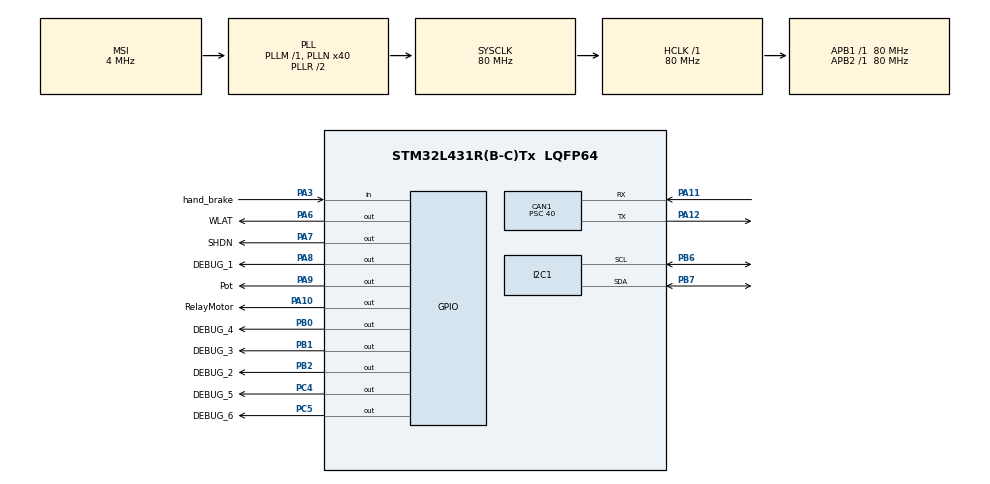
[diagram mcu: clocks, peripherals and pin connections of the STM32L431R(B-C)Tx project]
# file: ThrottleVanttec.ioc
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CAN1.BS1=CAN_BS1_13TQ
CAN1.BS2=CAN_BS2_2TQ
CAN1.CalculateBaudRate=125000
CAN1.CalculateTimeBit=8000
CAN1.CalculateTimeQuantum=500.0
CAN1.Prescaler=40
FREERTOS.Tasks01=defaultTask,24,128,StartDefaultTask,Default,NULL,Dynamic,NULL,NULL
FREERTOS.configTOTAL_HEAP_SIZE=16000
FREERTOS.configUSE_NEWLIB_REENTRANT=1
I2C1.Timing=0x10909CEC
Mcu.Family=STM32L4
Mcu.Name=STM32L431R(B-C)Tx
Mcu.Package=LQFP64
NVIC.PriorityGroup=NVIC_PRIORITYGROUP_4
PA10.GPIO_Label=RelayMotor
PA10.Signal=GPIO_Output
PA11.Mode=CAN_Activate
PA11.Signal=CAN1_RX
PA12.Mode=CAN_Activate
PA12.Signal=CAN1_TX
PA3.GPIO_Label=hand_brake
PA3.Signal=GPIO_Input
PA6.GPIO_Label=WLAT
PA6.Signal=GPIO_Output
PA7.GPIO_Label=SHDN
PA7.Signal=GPIO_Output
PA8.GPIO_Label=DEBUG_1
PA8.Signal=GPIO_Output
PA9.GPIO_Label=Pot
PA9.Signal=GPIO_Output
PB0.GPIO_Label=DEBUG_4
PB0.Signal=GPIO_Output
PB1.GPIO_Label=DEBUG_3
PB1.Signal=GPIO_Output
PB2.GPIO_Label=DEBUG_2
PB2.Signal=GPIO_Output
PB6.Mode=I2C
PB6.Signal=I2C1_SCL
PB7.Mode=I2C
PB7.Signal=I2C1_SDA
PC4.GPIO_Label=DEBUG_5
PC4.Signal=GPIO_Output
PC5.GPIO_Label=DEBUG_6
PC5.Signal=GPIO_Output
ProjectManager.HeapSize=0x200
ProjectManager.StackSize=0x400
ProjectManager.TargetToolchain=STM32CubeIDE
RCC.AHBFreq_Value=80000000
RCC.APB1Freq_Value=80000000
RCC.APB1TimFreq_Value=80000000
RCC.APB2Freq_Value=80000000
RCC.APB2TimFreq_Value=80000000
RCC.CortexFreq_Value=80000000
RCC.HCLKFreq_Value=80000000
RCC.HSE_VALUE=8000000
RCC.HSI48_VALUE=48000000
RCC.HSI_VALUE=16000000
RCC.LSE_VALUE=32768
RCC.MSI_VALUE=4000000
RCC.PLLN=40
RCC.SYSCLKFreq_VALUE=80000000
RCC.SYSCLKSource=RCC_SYSCLKSOURCE_PLLCLK
RCC.VCOOutputFreq_Value=160000000
VP_FREERTOS_VS_CMSIS_V2.Mode=CMSIS_V2
board=custom

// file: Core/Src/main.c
/* USER CODE BEGIN Header */
/**
  ******************************************************************************
  * @file           : main.c
  * @brief          : Main program body
  ******************************************************************************
  * @attention
  *
  * Copyright (c) 2023 STMicroelectronics.
  * All rights reserved.
  *
  * This software is licensed under terms that can be found in the LICENSE file
  * in the root directory of this software component.
  * If no LICENSE file comes with this software, it is provided AS-IS.
  *
  ******************************************************************************
  */
/* USER CODE END Header */
#include "main.h"
#include "cmsis_os.h"

/* USER CODE BEGIN Includes */
#include "mcp45hvx1.h"
#include "throttle_tasks.h"
#include "requirements.h"
#include "vanttec_sdv_ids.h"

/* USER CODE END Includes */

CAN_HandleTypeDef hcan1;

I2C_HandleTypeDef hi2c1;

/* Definitions for defaultTask */
osThreadId_t defaultTaskHandle;
const osThreadAttr_t defaultTask_attributes = {
  .name = "defaultTask",
  .stack_size = 128 * 4,
  .priority = (osPriority_t) osPriorityNormal,
};

void SystemClock_Config(void);
static void MX_GPIO_Init(void);
static void MX_CAN1_Init(void);
static void MX_I2C1_Init(void);
void StartDefaultTask(void *argument);

int main(void)
{

  /* MCU Configuration--------------------------------------------------------*/

  /* Reset of all peripherals, Initializes the Flash interface and the Systick. */
  HAL_Init();

  /* Configure the system clock */
  SystemClock_Config();

  /* Initialize all configured peripherals */
  MX_GPIO_Init();
  MX_CAN1_Init();
  MX_I2C1_Init();
  /* USER CODE BEGIN 2 */
  init_canlib(hcan1, VANTTEC_CAN_ID_THROTTLE_TX);
  init_canlib_tx();
  init_canlib_rx();
  canlib_init_generic_tasks();
  //init_ping_task();
  initialize_devices();
  begin_pot();
  init_requirements_task();
  init_throttle_tasks();
  /* USER CODE END 2 */

  /* Init scheduler */
  osKernelInitialize();

  /* Create the thread(s) */
  /* creation of defaultTask */
  defaultTaskHandle = osThreadNew(StartDefaultTask, NULL, &defaultTask_attributes);

  /* Start scheduler */
  osKernelStart();

  /* We should never get here as control is now taken by the scheduler */
  /* Infinite loop */
  while (1)
  {

  }
}

void SystemClock_Config(void)
{
  RCC_OscInitTypeDef RCC_OscInitStruct = {0};
  RCC_ClkInitTypeDef RCC_ClkInitStruct = {0};

  /** Configure the main internal regulator output voltage
  */
  if (HAL_PWREx_ControlVoltageScaling(PWR_REGULATOR_VOLTAGE_SCALE1) != HAL_OK)
  {
    Error_Handler();
  }

  /** Initializes the RCC Oscillators according to the specified parameters
  * in the RCC_OscInitTypeDef structure.
  */
  RCC_OscInitStruct.OscillatorType = RCC_OSCILLATORTYPE_MSI;
  RCC_OscInitStruct.MSIState = RCC_MSI_ON;
  RCC_OscInitStruct.MSICalibrationValue = 0;
  RCC_OscInitStruct.MSIClockRange = RCC_MSIRANGE_6;
  RCC_OscInitStruct.PLL.PLLState = RCC_PLL_ON;
  RCC_OscInitStruct.PLL.PLLSource = RCC_PLLSOURCE_MSI;
  RCC_OscInitStruct.PLL.PLLM = 1;
  RCC_OscInitStruct.PLL.PLLN = 40;
  RCC_OscInitStruct.PLL.PLLP = RCC_PLLP_DIV7;
  RCC_OscInitStruct.PLL.PLLQ = RCC_PLLQ_DIV2;
  RCC_OscInitStruct.PLL.PLLR = RCC_PLLR_DIV2;
  if (HAL_RCC_OscConfig(&RCC_OscInitStruct) != HAL_OK)
  {
    Error_Handler();
  }

  /** Initializes the CPU, AHB and APB buses clocks
  */
  RCC_ClkInitStruct.ClockType = RCC_CLOCKTYPE_HCLK|RCC_CLOCKTYPE_SYSCLK
                              |RCC_CLOCKTYPE_PCLK1|RCC_CLOCKTYPE_PCLK2;
  RCC_ClkInitStruct.SYSCLKSource = RCC_SYSCLKSOURCE_PLLCLK;
  RCC_ClkInitStruct.AHBCLKDivider = RCC_SYSCLK_DIV1;
  RCC_ClkInitStruct.APB1CLKDivider = RCC_HCLK_DIV1;
  RCC_ClkInitStruct.APB2CLKDivider = RCC_HCLK_DIV1;

  if (HAL_RCC_ClockConfig(&RCC_ClkInitStruct, FLASH_LATENCY_4) != HAL_OK)
  {
    Error_Handler();
  }
}

static void MX_CAN1_Init(void)
{

  hcan1.Instance = CAN1;
  hcan1.Init.Prescaler = 40;
  hcan1.Init.Mode = CAN_MODE_NORMAL;
  hcan1.Init.SyncJumpWidth = CAN_SJW_1TQ;
  hcan1.Init.TimeSeg1 = CAN_BS1_13TQ;
  hcan1.Init.TimeSeg2 = CAN_BS2_2TQ;
  hcan1.Init.TimeTriggeredMode = DISABLE;
  hcan1.Init.AutoBusOff = DISABLE;
  hcan1.Init.AutoWakeUp = DISABLE;
  hcan1.Init.AutoRetransmission = DISABLE;
  hcan1.Init.ReceiveFifoLocked = DISABLE;
  hcan1.Init.TransmitFifoPriority = DISABLE;
  if (HAL_CAN_Init(&hcan1) != HAL_OK)
  {
    Error_Handler();
  }

}

static void MX_I2C1_Init(void)
{

  hi2c1.Instance = I2C1;
  hi2c1.Init.Timing = 0x10909CEC;
  hi2c1.Init.OwnAddress1 = 0;
  hi2c1.Init.AddressingMode = I2C_ADDRESSINGMODE_7BIT;
  hi2c1.Init.DualAddressMode = I2C_DUALADDRESS_DISABLE;
  hi2c1.Init.OwnAddress2 = 0;
  hi2c1.Init.OwnAddress2Masks = I2C_OA2_NOMASK;
  hi2c1.Init.GeneralCallMode = I2C_GENERALCALL_DISABLE;
  hi2c1.Init.NoStretchMode = I2C_NOSTRETCH_DISABLE;
  if (HAL_I2C_Init(&hi2c1) != HAL_OK)
  {
    Error_Handler();
  }

  /** Configure Analogue filter
  */
  if (HAL_I2CEx_ConfigAnalogFilter(&hi2c1, I2C_ANALOGFILTER_ENABLE) != HAL_OK)
  {
    Error_Handler();
  }

  /** Configure Digital filter
  */
  if (HAL_I2CEx_ConfigDigitalFilter(&hi2c1, 0) != HAL_OK)
  {
    Error_Handler();
  }

}

static void MX_GPIO_Init(void)
{
  GPIO_InitTypeDef GPIO_InitStruct = {0};

  /* GPIO Ports Clock Enable */
  __HAL_RCC_GPIOA_CLK_ENABLE();
  __HAL_RCC_GPIOC_CLK_ENABLE();
  __HAL_RCC_GPIOB_CLK_ENABLE();

  /*Configure GPIO pin Output Level */
  HAL_GPIO_WritePin(GPIOA, WLAT_Pin|SHDN_Pin|DEBUG_1_Pin|Pot_Pin
                          |RelayMotor_Pin, GPIO_PIN_RESET);

  /*Configure GPIO pin Output Level */
  HAL_GPIO_WritePin(GPIOC, DEBUG_5_Pin|DEBUG_6_Pin, GPIO_PIN_RESET);

  /*Configure GPIO pin Output Level */
  HAL_GPIO_WritePin(GPIOB, DEBUG_4_Pin|DEBUG_3_Pin|DEBUG_2_Pin, GPIO_PIN_RESET);

  /*Configure GPIO pin : hand_brake_Pin */
  GPIO_InitStruct.Pin = hand_brake_Pin;
  GPIO_InitStruct.Mode = GPIO_MODE_INPUT;
  GPIO_InitStruct.Pull = GPIO_NOPULL;
  HAL_GPIO_Init(hand_brake_GPIO_Port, &GPIO_InitStruct);

  /*Configure GPIO pins : WLAT_Pin SHDN_Pin DEBUG_1_Pin Pot_Pin
                           RelayMotor_Pin */
  GPIO_InitStruct.Pin = WLAT_Pin|SHDN_Pin|DEBUG_1_Pin|Pot_Pin
                          |RelayMotor_Pin;
  GPIO_InitStruct.Mode = GPIO_MODE_OUTPUT_PP;
  GPIO_InitStruct.Pull = GPIO_NOPULL;
  GPIO_InitStruct.Speed = GPIO_SPEED_FREQ_LOW;
  HAL_GPIO_Init(GPIOA, &GPIO_InitStruct);

  /*Configure GPIO pins : DEBUG_5_Pin DEBUG_6_Pin */
  GPIO_InitStruct.Pin = DEBUG_5_Pin|DEBUG_6_Pin;
  GPIO_InitStruct.Mode = GPIO_MODE_OUTPUT_PP;
  GPIO_InitStruct.Pull = GPIO_NOPULL;
  GPIO_InitStruct.Speed = GPIO_SPEED_FREQ_LOW;
  HAL_GPIO_Init(GPIOC, &GPIO_InitStruct);

  /*Configure GPIO pins : DEBUG_4_Pin DEBUG_3_Pin DEBUG_2_Pin */
  GPIO_InitStruct.Pin = DEBUG_4_Pin|DEBUG_3_Pin|DEBUG_2_Pin;
  GPIO_InitStruct.Mode = GPIO_MODE_OUTPUT_PP;
  GPIO_InitStruct.Pull = GPIO_NOPULL;
  GPIO_InitStruct.Speed = GPIO_SPEED_FREQ_LOW;
  HAL_GPIO_Init(GPIOB, &GPIO_InitStruct);

}

void StartDefaultTask(void *argument)
{
  for(;;)
  {
    osDelay(1);
  }
}

void Error_Handler(void)
{
  __disable_irq();
  while (1)
  {
  }
}
